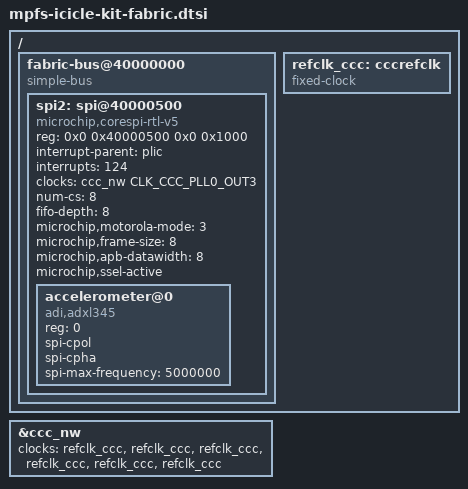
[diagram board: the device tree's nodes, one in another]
/*
 * Copyright (c) 2025 Linaro Limited
 *
 * SPDX-License-Identifier: Apache-2.0
 */

/ {
	fabric-bus@40000000 {
		compatible = "simple-bus";
		#address-cells = <2>;
		#size-cells = <2>;
		ranges = <0x0 0x40000000 0x0 0x40000000 0x0 0x20000000>, /* FIC3-FAB */
			 <0x0 0x60000000 0x0 0x60000000 0x0 0x20000000>, /* FIC0, LO */
			 <0x0 0xe0000000 0x0 0xe0000000 0x0 0x20000000>, /* FIC1, LO */
			 <0x20 0x0 0x20 0x0 0x10 0x0>, /* FIC0,HI */
			 <0x30 0x0 0x30 0x0 0x10 0x0>; /* FIC1,HI */
       
        spi2: spi@40000500 {
            compatible = "microchip,corespi-rtl-v5";
            #address-cells = <1>;
            #size-cells = <0>;
            reg = <0x0 0x40000500 0x0 0x1000>;
            interrupt-parent = <&plic>;
            interrupts = <124>;
            clocks = <&ccc_nw CLK_CCC_PLL0_OUT3>;
            num-cs = <8>;
            fifo-depth = <8>;
            microchip,motorola-mode = <3>;
            microchip,frame-size = <8>;
            microchip,apb-datawidth = <8>;
            microchip,ssel-active;
 
            accelerometer@0 {
                compatible = "adi,adxl345";
                reg = <0>;
                spi-cpol;
                spi-cpha;
                spi-max-frequency = <5000000>;  
            };
        };
	};

	refclk_ccc: cccrefclk {
		compatible = "fixed-clock";
		#clock-cells = <0>;
	};

	refclk_ccc: cccrefclk {
		compatible = "fixed-clock";
		#clock-cells = <0>;
	};
};

&ccc_nw {
	clocks = <&refclk_ccc>, <&refclk_ccc>, <&refclk_ccc>, <&refclk_ccc>,
		 <&refclk_ccc>, <&refclk_ccc>;
	clock-names = "pll0_ref0", "pll0_ref1", "pll1_ref0", "pll1_ref1",
		      "dll0_ref", "dll1_ref";
	status = "okay";
};
